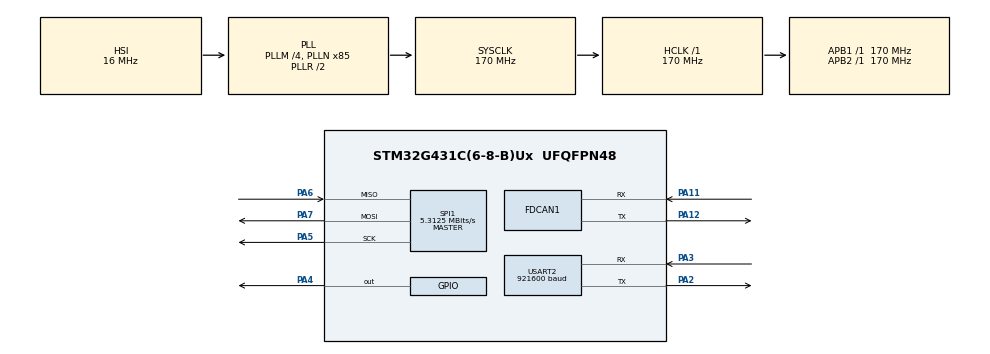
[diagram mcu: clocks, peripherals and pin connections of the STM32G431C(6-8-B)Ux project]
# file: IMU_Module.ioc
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Dma.Request0=SPI1_RX
Dma.Request1=SPI1_TX
Dma.Request2=USART2_RX
Dma.Request3=USART2_TX
Dma.SPI1_RX.0.Direction=DMA_PERIPH_TO_MEMORY
Dma.SPI1_RX.0.EventEnable=DISABLE
Dma.SPI1_RX.0.Instance=DMA1_Channel1
Dma.SPI1_RX.0.MemDataAlignment=DMA_MDATAALIGN_BYTE
Dma.SPI1_RX.0.MemInc=DMA_MINC_ENABLE
Dma.SPI1_RX.0.Mode=DMA_NORMAL
Dma.SPI1_RX.0.PeriphDataAlignment=DMA_PDATAALIGN_BYTE
Dma.SPI1_RX.0.PeriphInc=DMA_PINC_DISABLE
Dma.SPI1_RX.0.Polarity=HAL_DMAMUX_REQ_GEN_RISING
Dma.SPI1_RX.0.Priority=DMA_PRIORITY_LOW
Dma.SPI1_RX.0.RequestNumber=1
Dma.SPI1_RX.0.SignalID=NONE
Dma.SPI1_RX.0.SyncEnable=DISABLE
Dma.SPI1_RX.0.SyncPolarity=HAL_DMAMUX_SYNC_NO_EVENT
Dma.SPI1_RX.0.SyncRequestNumber=1
Dma.SPI1_RX.0.SyncSignalID=NONE
Dma.SPI1_TX.1.Direction=DMA_MEMORY_TO_PERIPH
Dma.SPI1_TX.1.EventEnable=DISABLE
Dma.SPI1_TX.1.Instance=DMA1_Channel2
Dma.SPI1_TX.1.MemDataAlignment=DMA_MDATAALIGN_BYTE
Dma.SPI1_TX.1.MemInc=DMA_MINC_ENABLE
Dma.SPI1_TX.1.Mode=DMA_NORMAL
Dma.SPI1_TX.1.PeriphDataAlignment=DMA_PDATAALIGN_BYTE
Dma.SPI1_TX.1.PeriphInc=DMA_PINC_DISABLE
Dma.SPI1_TX.1.Polarity=HAL_DMAMUX_REQ_GEN_RISING
Dma.SPI1_TX.1.Priority=DMA_PRIORITY_LOW
Dma.SPI1_TX.1.RequestNumber=1
Dma.SPI1_TX.1.SignalID=NONE
Dma.SPI1_TX.1.SyncEnable=DISABLE
Dma.SPI1_TX.1.SyncPolarity=HAL_DMAMUX_SYNC_NO_EVENT
Dma.SPI1_TX.1.SyncRequestNumber=1
Dma.SPI1_TX.1.SyncSignalID=NONE
Dma.USART2_RX.2.Direction=DMA_PERIPH_TO_MEMORY
Dma.USART2_RX.2.EventEnable=DISABLE
Dma.USART2_RX.2.Instance=DMA1_Channel3
Dma.USART2_RX.2.MemDataAlignment=DMA_MDATAALIGN_BYTE
Dma.USART2_RX.2.MemInc=DMA_MINC_ENABLE
Dma.USART2_RX.2.Mode=DMA_NORMAL
Dma.USART2_RX.2.PeriphDataAlignment=DMA_PDATAALIGN_BYTE
Dma.USART2_RX.2.PeriphInc=DMA_PINC_DISABLE
Dma.USART2_RX.2.Polarity=HAL_DMAMUX_REQ_GEN_RISING
Dma.USART2_RX.2.Priority=DMA_PRIORITY_LOW
Dma.USART2_RX.2.RequestNumber=1
Dma.USART2_RX.2.SignalID=NONE
Dma.USART2_RX.2.SyncEnable=DISABLE
Dma.USART2_RX.2.SyncPolarity=HAL_DMAMUX_SYNC_NO_EVENT
Dma.USART2_RX.2.SyncRequestNumber=1
Dma.USART2_RX.2.SyncSignalID=NONE
Dma.USART2_TX.3.Direction=DMA_MEMORY_TO_PERIPH
Dma.USART2_TX.3.EventEnable=DISABLE
Dma.USART2_TX.3.Instance=DMA1_Channel4
Dma.USART2_TX.3.MemDataAlignment=DMA_MDATAALIGN_BYTE
Dma.USART2_TX.3.MemInc=DMA_MINC_ENABLE
Dma.USART2_TX.3.Mode=DMA_NORMAL
Dma.USART2_TX.3.PeriphDataAlignment=DMA_PDATAALIGN_BYTE
Dma.USART2_TX.3.PeriphInc=DMA_PINC_DISABLE
Dma.USART2_TX.3.Polarity=HAL_DMAMUX_REQ_GEN_RISING
Dma.USART2_TX.3.Priority=DMA_PRIORITY_LOW
Dma.USART2_TX.3.RequestNumber=1
Dma.USART2_TX.3.SignalID=NONE
Dma.USART2_TX.3.SyncEnable=DISABLE
Dma.USART2_TX.3.SyncPolarity=HAL_DMAMUX_SYNC_NO_EVENT
Dma.USART2_TX.3.SyncRequestNumber=1
Dma.USART2_TX.3.SyncSignalID=NONE
FDCAN1.CalculateBaudRateNominal=1000000
FDCAN1.CalculateTimeBitNominal=1000
FDCAN1.CalculateTimeQuantumNominal=100.0
FDCAN1.NominalPrescaler=17
FDCAN1.NominalTimeSeg1=7
FDCAN1.NominalTimeSeg2=2
FDCAN1.StdFiltersNbr=1
FREERTOS.TOTAL_HEAP_SIZE=12288
FREERTOS.INCLUDE_vTaskDelayUntil=Enabled
FREERTOS.Tasks01=defaultTask,0,1024,StartDefaultTask,Default,NULL,Dynamic,NULL,NULL
Mcu.Family=STM32G4
Mcu.Name=STM32G431C(6-8-B)Ux
Mcu.Package=UFQFPN48
NVIC.DMA1_Channel1_IRQn=true\:5\:0\:false\:false\:true\:true\:false\:true\:true
NVIC.DMA1_Channel2_IRQn=true\:5\:0\:false\:false\:true\:true\:false\:true\:true
NVIC.DMA1_Channel3_IRQn=true\:5\:0\:false\:false\:true\:true\:false\:true\:true
NVIC.DMA1_Channel4_IRQn=true\:5\:0\:false\:false\:true\:true\:false\:true\:true
NVIC.FDCAN1_IT0_IRQn=true\:5\:0\:false\:false\:true\:true\:true\:true\:true
NVIC.FDCAN1_IT1_IRQn=true\:5\:0\:false\:false\:true\:true\:true\:true\:true
NVIC.PriorityGroup=NVIC_PRIORITYGROUP_4
NVIC.SPI1_IRQn=true\:5\:0\:false\:false\:true\:true\:true\:true\:true
NVIC.TIM6_DAC_IRQn=true\:15\:0\:false\:false\:true\:false\:false\:true\:true
NVIC.TimeBase=TIM6_DAC_IRQn
NVIC.TimeBaseIP=TIM6
NVIC.USART2_IRQn=true\:5\:0\:false\:false\:true\:true\:true\:true\:true
PA11.Mode=FDCAN_Activate
PA11.Signal=FDCAN1_RX
PA12.Mode=FDCAN_Activate
PA12.Signal=FDCAN1_TX
PA13.Mode=Serial_Wire
PA13.Signal=SYS_JTMS-SWDIO
PA14.Mode=Serial_Wire
PA14.Signal=SYS_JTCK-SWCLK
PA2.Mode=Asynchronous
PA2.Signal=USART2_TX
PA3.Mode=Asynchronous
PA3.Signal=USART2_RX
PA4.GPIO_ModeDefaultOutputPP=GPIO_MODE_OUTPUT_PP
PA4.GPIO_PuPd=GPIO_PULLUP
PA4.PinState=GPIO_PIN_SET
PA4.Signal=GPIO_Output
PA5.Mode=Full_Duplex_Master
PA5.Signal=SPI1_SCK
PA6.Mode=Full_Duplex_Master
PA6.Signal=SPI1_MISO
PA7.Mode=Full_Duplex_Master
PA7.Signal=SPI1_MOSI
PF0-OSC_IN.Mode=HSE-External-Oscillator
PF0-OSC_IN.Signal=RCC_OSC_IN
PF1-OSC_OUT.Mode=HSE-External-Oscillator
PF1-OSC_OUT.Signal=RCC_OSC_OUT
ProjectManager.HeapSize=0x200
ProjectManager.StackSize=0x400
ProjectManager.TargetToolchain=CMake
RCC.ADC12Freq_Value=170000000
RCC.AHBFreq_Value=170000000
RCC.APB1Freq_Value=170000000
RCC.APB1TimFreq_Value=170000000
RCC.APB2Freq_Value=170000000
RCC.APB2TimFreq_Value=170000000
RCC.CortexFreq_Value=170000000
RCC.EXTERNAL_CLOCK_VALUE=12288000
RCC.HCLKFreq_Value=170000000
RCC.HSE_VALUE=8000000
RCC.HSI48_VALUE=48000000
RCC.HSI_VALUE=16000000
RCC.LSE_VALUE=32768
RCC.PLLM=RCC_PLLM_DIV4
RCC.PLLN=85
RCC.SYSCLKFreq_VALUE=170000000
RCC.SYSCLKSource=RCC_SYSCLKSOURCE_PLLCLK
RCC.USBFreq_Value=170000000
RCC.VCOOutputFreq_Value=340000000
SPI1.BaudRatePrescaler=SPI_BAUDRATEPRESCALER_32
SPI1.CalculateBaudRate=5.3125 MBits/s
SPI1.DataSize=SPI_DATASIZE_8BIT
SPI1.Direction=SPI_DIRECTION_2LINES
SPI1.Mode=SPI_MODE_MASTER
SPI1.NSSPMode=SPI_NSS_PULSE_DISABLE
SPI1.VirtualType=VM_MASTER
USART2.BaudRate=921600
USART2.VirtualMode-Asynchronous=VM_ASYNC
VP_FREERTOS_VS_CMSIS_V1.Mode=CMSIS_V1
VP_SYS_VS_DBSignals.Mode=DisableDeadBatterySignals
VP_SYS_VS_tim6.Mode=TIM6
board=custom

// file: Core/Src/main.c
/* USER CODE BEGIN Header */
/**
  ******************************************************************************
  * @file           : main.c
  * @brief          : Main program body
  ******************************************************************************
  * @attention
  *
  * Copyright (c) 2026 STMicroelectronics.
  * All rights reserved.
  *
  * This software is licensed under terms that can be found in the LICENSE file
  * in the root directory of this software component.
  * If no LICENSE file comes with this software, it is provided AS-IS.
  *
  ******************************************************************************
  */
/* USER CODE END Header */
#include "main.h"
#include "cmsis_os.h"
#include "dma.h"
#include "fdcan.h"
#include "spi.h"
#include "usart.h"
#include "gpio.h"

void SystemClock_Config(void);
void MX_FREERTOS_Init(void);

int main(void)
{

  /* MCU Configuration--------------------------------------------------------*/

  /* Reset of all peripherals, Initializes the Flash interface and the Systick. */
  HAL_Init();

  /* Configure the system clock */
  SystemClock_Config();

  /* Initialize all configured peripherals */
  MX_GPIO_Init();
  MX_DMA_Init();
  MX_SPI1_Init();
  MX_FDCAN1_Init();
  MX_USART2_UART_Init();

  /* Call init function for freertos objects (in cmsis_os2.c) */
  MX_FREERTOS_Init();

  /* Start scheduler */
  osKernelStart();

  /* We should never get here as control is now taken by the scheduler */

  /* Infinite loop */
  while (1)
  {

  }
}

void SystemClock_Config(void)
{
  RCC_OscInitTypeDef RCC_OscInitStruct = {0};
  RCC_ClkInitTypeDef RCC_ClkInitStruct = {0};

  /** Configure the main internal regulator output voltage
  */
  HAL_PWREx_ControlVoltageScaling(PWR_REGULATOR_VOLTAGE_SCALE1_BOOST);

  /** Initializes the RCC Oscillators according to the specified parameters
  * in the RCC_OscInitTypeDef structure.
  */
  RCC_OscInitStruct.OscillatorType = RCC_OSCILLATORTYPE_HSI;
  RCC_OscInitStruct.HSIState = RCC_HSI_ON;
  RCC_OscInitStruct.HSICalibrationValue = RCC_HSICALIBRATION_DEFAULT;
  RCC_OscInitStruct.PLL.PLLState = RCC_PLL_ON;
  RCC_OscInitStruct.PLL.PLLSource = RCC_PLLSOURCE_HSI;
  RCC_OscInitStruct.PLL.PLLM = RCC_PLLM_DIV4;
  RCC_OscInitStruct.PLL.PLLN = 85;
  RCC_OscInitStruct.PLL.PLLP = RCC_PLLP_DIV2;
  RCC_OscInitStruct.PLL.PLLQ = RCC_PLLQ_DIV2;
  RCC_OscInitStruct.PLL.PLLR = RCC_PLLR_DIV2;
  if (HAL_RCC_OscConfig(&RCC_OscInitStruct) != HAL_OK)
  {
    Error_Handler();
  }

  /** Initializes the CPU, AHB and APB buses clocks
  */
  RCC_ClkInitStruct.ClockType = RCC_CLOCKTYPE_HCLK|RCC_CLOCKTYPE_SYSCLK
                              |RCC_CLOCKTYPE_PCLK1|RCC_CLOCKTYPE_PCLK2;
  RCC_ClkInitStruct.SYSCLKSource = RCC_SYSCLKSOURCE_PLLCLK;
  RCC_ClkInitStruct.AHBCLKDivider = RCC_SYSCLK_DIV1;
  RCC_ClkInitStruct.APB1CLKDivider = RCC_HCLK_DIV1;
  RCC_ClkInitStruct.APB2CLKDivider = RCC_HCLK_DIV1;

  if (HAL_RCC_ClockConfig(&RCC_ClkInitStruct, FLASH_LATENCY_4) != HAL_OK)
  {
    Error_Handler();
  }
}

void HAL_TIM_PeriodElapsedCallback(TIM_HandleTypeDef *htim)
{
  if (htim->Instance == TIM6)
  {
    HAL_IncTick();
  }
}

void Error_Handler(void)
{
  __disable_irq();
  while (1)
  {
  }
}

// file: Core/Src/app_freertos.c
/* USER CODE BEGIN Header */
/**
  ******************************************************************************
  * File Name          : app_freertos.c
  * Description        : Code for freertos applications
  ******************************************************************************
  * @attention
  *
  * Copyright (c) 2026 STMicroelectronics.
  * All rights reserved.
  *
  * This software is licensed under terms that can be found in the LICENSE file
  * in the root directory of this software component.
  * If no LICENSE file comes with this software, it is provided AS-IS.
  *
  ******************************************************************************
  */
/* USER CODE END Header */

#include "FreeRTOS.h"
#include "task.h"
#include "main.h"
#include "cmsis_os.h"

/* USER CODE BEGIN Includes */
#include "imu_module.h"
/* USER CODE END Includes */

osThreadId defaultTaskHandle;

void StartDefaultTask(void const * argument);

void MX_FREERTOS_Init(void); /* (MISRA C 2004 rule 8.1) */

void MX_FREERTOS_Init(void) {

  /* Create the thread(s) */
  /* definition and creation of defaultTask
   * 移植调整：256 词（1 KB）时，imu_module_init() 的调用链
   *   imu_module_init → imu_service_start → capture.init() → s_imu.init()
   *   → calibrate() → read() → SPI 中间件 → 驱动解包
   * 在 -O0 下累计栈帧超过 1 KB，会踩坏 FreeRTOS 堆中相邻的 TCB / 任务栈，
   * 表现为运行约 1 秒后 PendSV 恢复上下文时 r3 为垃圾值 → HardFault。
   * 这里给到 1024 词（4 KB），留足余量。 */
  osThreadDef(defaultTask, StartDefaultTask, osPriorityNormal, 0, 1024);
  defaultTaskHandle = osThreadCreate(osThread(defaultTask), NULL);

}

void StartDefaultTask(void const * argument)
{
  /* USER CODE BEGIN StartDefaultTask */
  /* IMU 链路启动：调度器已运行，满足信号量 / HAL_Delay / DMA 等待前提。
   * 本调用内部完成器件初始化，并拉起【采集】与【融合+发布】两个常驻任务
   * （拆分原因见 Module/IMU/ins_service.cpp 文件头）。
   * 失败原因见 imu_module_init_result 与 imu_service_* 诊断量。 */
  (void)imu_module_init();

  /* 回收引导任务：初始化完成后本任务无事可做，自删归还 1024 词（4 KB）栈与 TCB。
   *
   * 为什么需要这一步（实测数据）：12 KB 堆里原本放
   *   defaultTask 4K + ins 4K + pub 1.5K + IDLE 0.5K + TCB ≈ 10 KB，余 3176 B。
   * 拆出采集任务后多出 ins_cap，若不回收引导任务则峰值超过 12288 B，
   * imu_pub 创建失败 -> imu_module_init_result = -4（已实测到该值）。
   *
   * 注意：vTaskDelete(NULL) 只是把本任务标记为待删，真正的栈回收发生在
   * idle 任务执行 prvCheckTasksWaitingTermination 时，因此【不能】指望
   * "删完立刻用回这 4 KB 去创建别的任务"。所以创建期的堆峰值必须靠
   * 另一条路压下来 —— 见 Module/Config/imu_config.h 里 ins_cap 的栈取值。
   * 这里自删的意义是：稳态运行期把 4 KB 还给系统（实测 heap_free 由
   * 创建期的紧张值回到约 4.7 KB）。 */
  vTaskDelete(NULL);

  /* 以下不可达，保留以明确语义 */
  for(;;)
  {
    osDelay(1);
  }
  /* USER CODE END StartDefaultTask */
}
